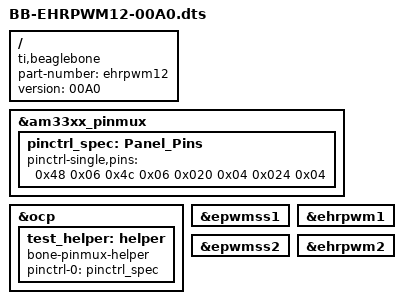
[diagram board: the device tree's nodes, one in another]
/dts-v1/;
/plugin/;

/ {
    compatible = "ti,beaglebone", "ti,beaglebone-black", "ti,beaglebone-green";

    // identification
    part-number = "ehrpwm12";
    version = "00A0";
    
    #address-cells = <1>;
    #size-cells = <0>;
    
    fragment@0 {
        target = <&am33xx_pinmux>;
        reg = <0>;
            __overlay__ {
            pinctrl_spec: Panel_Pins {
                    pinctrl-single,pins = <
                        0x48 0x06 /* (U14) gpmc_a2.ehrpwm1A */
                        0x4c 0x06 /* (T14) gpmc_a3.ehrpwm1B */
                        0x020 0x04 /* P8_19 MODE4 ehrpwm2A PWM */
                        0x024 0x04 /* P8_19 MODE4 ehrpwm2A PWM */
                    >;
                };
            };
    };

    fragment@1 {
        target = <&ocp>;
        reg = <1>;
            __overlay__ {
            test_helper: helper {
                compatible = "bone-pinmux-helper";
                pinctrl-names = "default";
                pinctrl-0 = <&pinctrl_spec>;
                status = "okay";
            };
        };
    };

    fragment@2 {
        target = <&epwmss1>;
        reg = <2>;
        __overlay__ {
            status = "okay";
        };
    };

    fragment@3 {
        reg = <3>;
        target = <&ehrpwm1>;
        __overlay__ {
            status = "okay";
        };
    };

    fragment@4 {
        target = <&epwmss2>;
        reg = <4>;
        __overlay__ {
            status = "okay";
        };
    };

    fragment@5 {
        target = <&ehrpwm2>;
        reg = <5>;
        __overlay__ {
            status = "okay";
        };
    };
};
